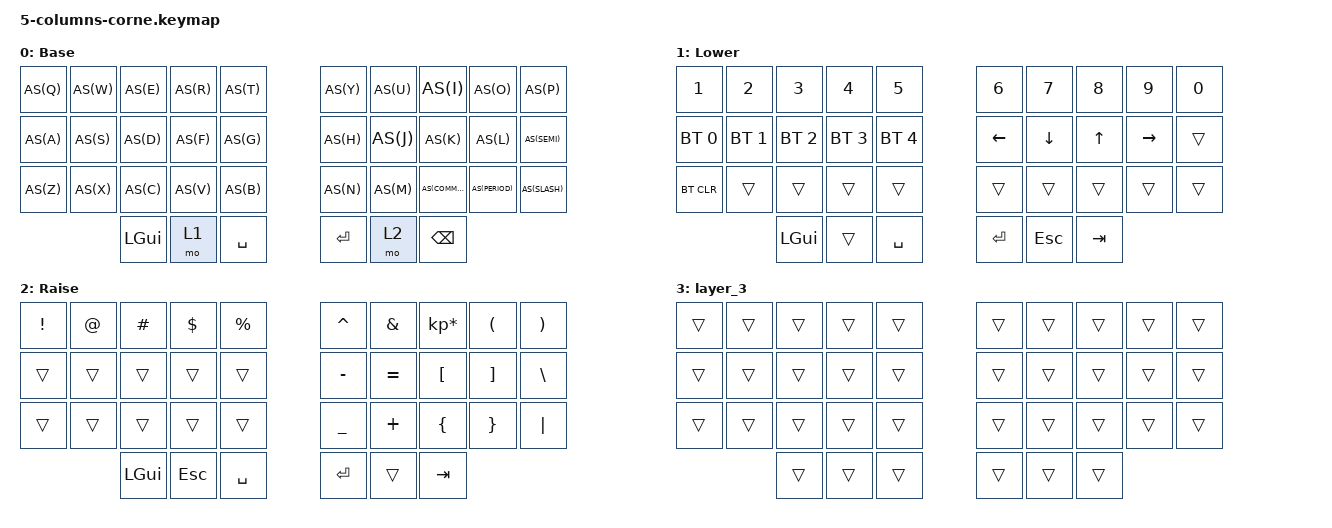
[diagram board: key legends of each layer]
/*
 * Copyright (c) 2020 The ZMK Contributors
 *
 * SPDX-License-Identifier: MIT
 */

#include <behaviors.dtsi>
#include <dt-bindings/zmk/bt.h>
#include <dt-bindings/zmk/keys.h>

#define AS(keycode) &as LS(keycode) keycode

/ {
    chosen { zmk,matrix_transform = &five_column_transform; };

    behaviors {
            as: auto_shift {
                compatible = "zmk,behavior-hold-tap";
                label = "AUTO_SHIFT";
                #binding-cells = <2>;
                tapping_term_ms = <200>;
                quick_tap_ms = <0>;
                flavor = "tap-preferred";
                bindings = <&kp>, <&kp>;
            };
        };

    keymap {
        compatible = "zmk,keymap";

        default_layer {
            // -----------------------------------------------------------------------------------------
            // |  Q  |  W  |  E  |  R  |  T  |     |  Y  |  U   |  I   |  O   | P |
            // |  A  |  S  |  D  |  F  |  G  |     |  H  |  J   |  K   |  L   | ' | 
            // |  Z  |  X  |  C  |  V  |  B  |     |  N  |  M   | CTRL | META | . |
            //             | GUI | LWR | SPC |     | ENT | RSE  | BSPC |

            display-name = "Base";
            bindings = <
  AS(Q)  AS(W)  AS(E)     AS(R)  AS(T)        AS(Y)    AS(U)  AS(I)      AS(O)       AS(P)
  AS(A)  AS(S)  AS(D)     AS(F)  AS(G)        AS(H)    AS(J)  AS(K)      AS(L)       AS(SEMI)
  AS(Z)  AS(X)  AS(C)     AS(V)  AS(B)        AS(N)    AS(M)  AS(COMMA)  AS(PERIOD)  AS(SLASH)
                &kp LGUI  &mo 1  &kp SPACE    &kp RET  &mo 2  &kp BSPC
            >;
        };

        lower_layer {
            // -----------------------------------------------------------------------------------------
            // |  1  　　　　|  2  |  3  |  4  |  5  |   　　　　|  6  |  7  |  8  |  9  |  0  |
            // | BT1   | BT2 | BT3 | BT4 | BT5 |     | LFT | DWN |  UP | RGT |     |
            // | BTCLR |     |     |     |     |     |     |     |     |     |     |
            //               | GUI |     | SPC |     | ENT | ESC | TAB |

            display-name = "Lower";
            bindings = <
  &kp N1        &kp N2        &kp N3        &kp N4        &kp N5          &kp N6     &kp N7    &kp N8   &kp N9     &kp N0
  &bt BT_SEL 0  &bt BT_SEL 1  &bt BT_SEL 2  &bt BT_SEL 3  &bt BT_SEL 4    &kp LEFT   &kp DOWN  &kp UP   &kp RIGHT  &trans
  &bt BT_CLR    &trans        &trans        &trans        &trans          &trans     &trans    &trans   &trans     &trans
                              &kp LGUI      &trans        &kp SPACE       &kp ENTER  &kp ESC   &kp TAB
            >;
        };

        raise_layer {
            // -----------------------------------------------------------------------------------------
            // |  !  |  @  |  #  |  $  |  %  |   |  ^  |  &  |  *  |  (  |  )  |
            // |     |     |     |     |     |   |  -  |  =  |  [  |  ]  |  \  |
            // |     |     |     |     |     |   |  _  |  +  |  {  |  }  | "|"　　|
            //            | GUI | ESC | SPC |     | ENT |     | TAB |

            display-name = "Raise";
            bindings = <
  &kp EXCL  &kp AT  &kp HASH  &kp DLLR  &kp PRCNT    &kp CARET  &kp AMPS   &kp KP_MULTIPLY  &kp LPAR  &kp RPAR
  &trans    &trans  &trans    &trans    &trans       &kp MINUS  &kp EQUAL  &kp LBKT         &kp RBKT  &kp BSLH
  &trans    &trans  &trans    &trans    &trans       &kp UNDER  &kp PLUS   &kp LBRC         &kp RBRC  &kp PIPE
                    &kp LGUI  &kp ESC   &kp SPACE    &kp ENTER  &trans     &kp TAB
            >;
        };

        layer_3 {
            bindings = <
  &trans  &trans  &trans  &trans  &trans    &trans  &trans  &trans  &trans  &trans
  &trans  &trans  &trans  &trans  &trans    &trans  &trans  &trans  &trans  &trans
  &trans  &trans  &trans  &trans  &trans    &trans  &trans  &trans  &trans  &trans
                  &trans  &trans  &trans    &trans  &trans  &trans
            >;
        };
    };
};
